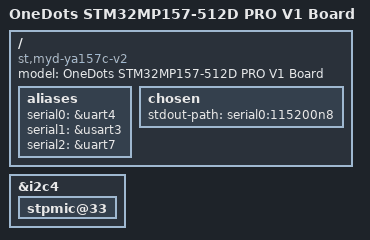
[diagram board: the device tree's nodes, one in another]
// SPDX-License-Identifier: (GPL-2.0+ OR BSD-3-Clause)


/dts-v1/;

#include "stm32mp157.dtsi"
#include "stm32mp15xa.dtsi"
#include "onedots_stm32mp15-pinctrl.dtsi"
#include "stm32mp15xxac-pinctrl.dtsi"
#include "onedots_stm32mp15xx.dtsi"
#include "stm32mp15-interrupt-fix.dtsi"

/ {
	model = "OneDots STM32MP157-512D PRO V1 Board";
	compatible = "st,myd-ya157c-v2", "st,stm32mp157";
	
	aliases {
		serial0 = &uart4;
		serial1 = &usart3;
		serial2 = &uart7;
	};

	chosen {
		stdout-path = "serial0:115200n8";
	};

};

/* This board has no STPMIC1 PMIC — remove compatible to prevent
 * TF-A v2.10 BL2 from attempting PMIC init (it forces DT_SECURE
 * status, bypassing the DT status property check).
 */
&i2c4 {
	stpmic@33 {
		/delete-property/ compatible;
	};
};
